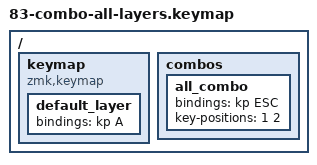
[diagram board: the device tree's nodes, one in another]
/* Issue #83: omitted layers means all layers. */
/ {
    keymap {
        compatible = "zmk,keymap";
        default_layer { bindings = <&kp A>; };
    };
    combos { all_combo { bindings = <&kp ESC>; key-positions = <1 2>; }; };

};
